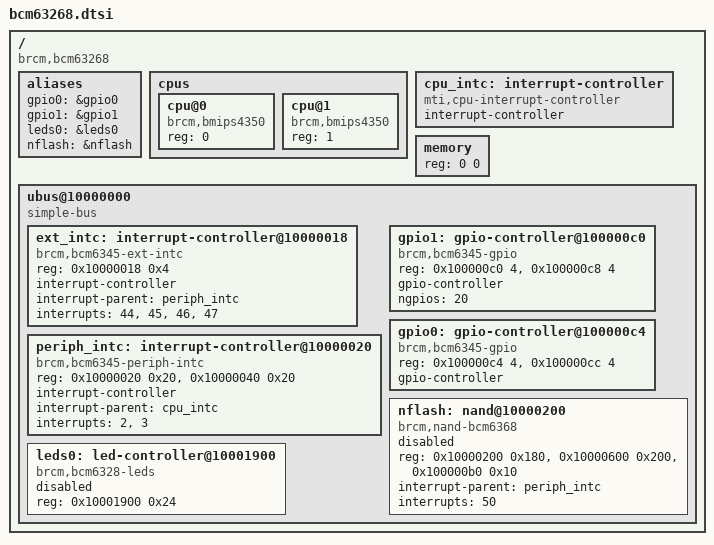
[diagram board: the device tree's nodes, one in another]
/ {
	#address-cells = <1>;
	#size-cells = <1>;
	compatible = "brcm,bcm63268";

	aliases {
		gpio0 = &gpio0;
		gpio1 = &gpio1;
		leds0 = &leds0;
		nflash = &nflash;
	};

	cpus {
		#address-cells = <1>;
		#size-cells = <0>;

		cpu@0 {
			compatible = "brcm,bmips4350", "mips,mips4Kc";
			device_type = "cpu";
			reg = <0>;
		};

		cpu@1 {
			compatible = "brcm,bmips4350", "mips,mips4Kc";
			device_type = "cpu";
			reg = <1>;
		};
	};

	cpu_intc: interrupt-controller {
		#address-cells = <0>;
		compatible = "mti,cpu-interrupt-controller";

		interrupt-controller;
		#interrupt-cells = <1>;
	};

	memory { device_type = "memory"; reg = <0 0>; };

	ubus@10000000 {
		#address-cells = <1>;
		#size-cells = <1>;
		ranges;
		compatible = "simple-bus";

		ext_intc: interrupt-controller@10000018 {
			compatible = "brcm,bcm6345-ext-intc";
			reg = <0x10000018 0x4>;

			interrupt-controller;
			#interrupt-cells = <2>;

			interrupt-parent = <&periph_intc>;
			interrupts = <44>, <45>, <46>, <47>;
		};

		periph_intc: interrupt-controller@10000020 {
			compatible = "brcm,bcm6345-periph-intc";
			reg = <0x10000020 0x20>,
			      <0x10000040 0x20>;

			interrupt-controller;
			#interrupt-cells = <1>;

			interrupt-parent = <&cpu_intc>;
			interrupts = <2>, <3>;
		};

		gpio1: gpio-controller@100000c0 {
			compatible = "brcm,bcm6345-gpio";
			reg = <0x100000c0 4>, <0x100000c8 4>;

			gpio-controller;
			#gpio-cells = <2>;

			ngpios = <20>;
		};

		gpio0: gpio-controller@100000c4 {
			compatible = "brcm,bcm6345-gpio";
			reg = <0x100000c4 4>, <0x100000cc 4>;

			gpio-controller;
			#gpio-cells = <2>;
		};

		nflash: nand@10000200 {
			#address-cells = <1>;
			#size-cells = <0>;
			compatible = "brcm,nand-bcm6368", "brcm,brcmnand-v4.0", "brcm,brcmnand";
			reg = <0x10000200 0x180>, <0x10000600 0x200>, <0x100000b0 0x10>;
			reg-names = "nand", "nand-cache", "nand-int-base";

			interrupt-parent = <&periph_intc>;
			interrupts = <50>;

			status = "disabled";
		};

		leds0: led-controller@10001900 {
			compatible = "brcm,bcm6328-leds";
			#address-cells = <1>;
			#size-cells = <0>;
			reg = <0x10001900 0x24>;

			status = "disabled";
		};
	};
};
